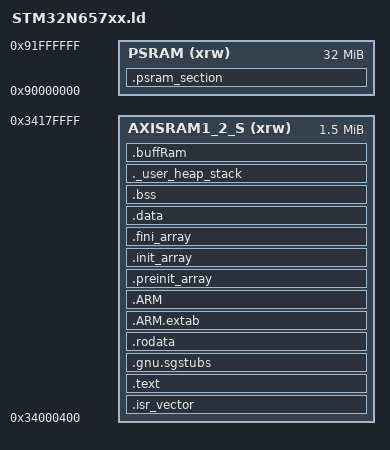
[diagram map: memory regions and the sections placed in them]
/*
******************************************************************************
**
** @file        : LinkerScript.ld
**
** @author      : Auto-generated by STM32CubeIDE
**
** @brief       : Linker script for STM32N657X0HxQ Device from STM32N6 series
**
**                Set heap size, stack size and stack location according
**                to application requirements.
**
**                Set memory bank area and size if external memory is used
**
**  Target      : STMicroelectronics STM32
**
**  Distribution: The file is distributed as is, without any warranty
**                of any kind.
**
******************************************************************************
** @attention
**
** Copyright (c) 2023 STMicroelectronics.
** All rights reserved.
**
** This software is licensed under terms that can be found in the LICENSE file
** in the root directory of this software component.
** If no LICENSE file comes with this software, it is provided AS-IS.
**
******************************************************************************
*/

/* Entry Point */
ENTRY(Reset_Handler)

/* Highest address of the user mode stack */
_estack = ORIGIN(AXISRAM1_2_S) + LENGTH(AXISRAM1_2_S); /* end of "AXISRAM1_2_S" Ram type memory */
_sstack = _estack - _Min_Stack_Size;

_Min_Heap_Size = 0x200; /* required amount of heap  */
_Min_Stack_Size = 0x1000; /* required amount of stack */

/* Memories definition */
/* Memory map used by ISP_IQTune_App:
 * - AXISRAM1_2_S: 0x34000400..0x3417FFFF
 *                 (application code/data, stack/heap, internal frame buffers)
 * - PSRAM:        0x90000000..0x91FFFFFF
 *                 (external large buffers: dump/overlay)
 *
 * Do not use AXISRAM2_S (0x34180000..0x341FFFFF) in this linker script.
 * This region is reserved for FSBL and must remain untouched by the app.
 */
MEMORY
{
  AXISRAM1_2_S      (xrw) : ORIGIN = 0x34000400, LENGTH = 1535k /* 2M-512k-1k */
  PSRAM             (xrw) : ORIGIN = 0x90000000, LENGTH =   32M
}

/* Sections */
SECTIONS
{
  /* The startup code into "RAM" Ram type memory */
  .isr_vector :
  {
    . = ALIGN(4);
    KEEP(*(.isr_vector)) /* Startup code */
    . = ALIGN(4);
  } >AXISRAM1_2_S

  /* The program code and other data into "RAM" Ram type memory */
  .text :
  {
    . = ALIGN(4);
    *(.text)           /* .text sections (code) */
    *(.text*)          /* .text* sections (code) */
    *(.glue_7)         /* glue arm to thumb code */
    *(.glue_7t)        /* glue thumb to arm code */
    *(.eh_frame)
    *(.RamFunc)        /* .RamFunc sections */
    *(.RamFunc*)       /* .RamFunc* sections */

    KEEP (*(.init))
    KEEP (*(.fini))

    . = ALIGN(4);
    _etext = .;        /* define a global symbols at end of code */
  } >AXISRAM1_2_S

  .gnu.sgstubs :
  {
    . = ALIGN(4);
    *(.gnu.sgstubs*)   /* Secure Gateway stubs */
    . = ALIGN(4);
  } >AXISRAM1_2_S

  /* Constant data into "RAM" Ram type memory */
  .rodata :
  {
    . = ALIGN(4);
    *(.rodata)         /* .rodata sections (constants, strings, etc.) */
    *(.rodata*)        /* .rodata* sections (constants, strings, etc.) */
    . = ALIGN(4);
  } >AXISRAM1_2_S

  .ARM.extab   : {
    . = ALIGN(4);
    *(.ARM.extab* .gnu.linkonce.armextab.*)
    . = ALIGN(4);
  } >AXISRAM1_2_S

  .ARM : {
    . = ALIGN(4);
    __exidx_start = .;
    *(.ARM.exidx*)
    __exidx_end = .;
    . = ALIGN(4);
  } >AXISRAM1_2_S

  .preinit_array     :
  {
    . = ALIGN(4);
    PROVIDE_HIDDEN (__preinit_array_start = .);
    KEEP (*(.preinit_array*))
    PROVIDE_HIDDEN (__preinit_array_end = .);
    . = ALIGN(4);
  } >AXISRAM1_2_S

  .init_array :
  {
    . = ALIGN(4);
    PROVIDE_HIDDEN (__init_array_start = .);
    KEEP (*(SORT(.init_array.*)))
    KEEP (*(.init_array*))
    PROVIDE_HIDDEN (__init_array_end = .);
    . = ALIGN(4);
  } >AXISRAM1_2_S

  .fini_array :
  {
    . = ALIGN(4);
    PROVIDE_HIDDEN (__fini_array_start = .);
    KEEP (*(SORT(.fini_array.*)))
    KEEP (*(.fini_array*))
    PROVIDE_HIDDEN (__fini_array_end = .);
    . = ALIGN(4);
  } >AXISRAM1_2_S

  /* Used by the startup to initialize data */
  _sidata = LOADADDR(.data);

  /* Initialized data sections into "RAM" Ram type memory */
  .data :
  {
    . = ALIGN(4);
    _sdata = .;        /* create a global symbol at data start */
    *(.data)           /* .data sections */
    *(.data*)          /* .data* sections */

    . = ALIGN(4);
    _edata = .;        /* define a global symbol at data end */

  } >AXISRAM1_2_S

  /* Uninitialized data section into "RAM" Ram type memory */
  . = ALIGN(4);
  .bss :
  {
    /* This is used by the startup in order to initialize the .bss section */
    _sbss = .;         /* define a global symbol at bss start */
    __bss_start__ = _sbss;
    *(.bss)
    *(.bss*)
    *(COMMON)

    . = ALIGN(4);
    _ebss = .;         /* define a global symbol at bss end */
    __bss_end__ = _ebss;
  } >AXISRAM1_2_S

  /* User_heap_stack section, used to check that there is enough "RAM" Ram  type memory left */
  ._user_heap_stack :
  {
    . = ALIGN(8);
    PROVIDE ( end = . );
    PROVIDE ( _end = . );
    . = . + _Min_Heap_Size;
    . = . + _Min_Stack_Size;
    . = ALIGN(8);
  } >AXISRAM1_2_S

  /* Camera frame buffer in internal RAM */
  .buffRam (NOLOAD):
  {
    . = ALIGN(4);
    *(.buffRam)
    . = ALIGN(4);
  } >AXISRAM1_2_S

  .psram_section (NOLOAD):
  {
     . = ALIGN(32);
    *(.psram_bss)
    . = ALIGN(32);
  } >PSRAM

  /* Remove information from the compiler libraries */
  /DISCARD/ :
  {
    libc.a ( * )
    libm.a ( * )
    libgcc.a ( * )
  }

  .ARM.attributes 0 : { *(.ARM.attributes) }
}
